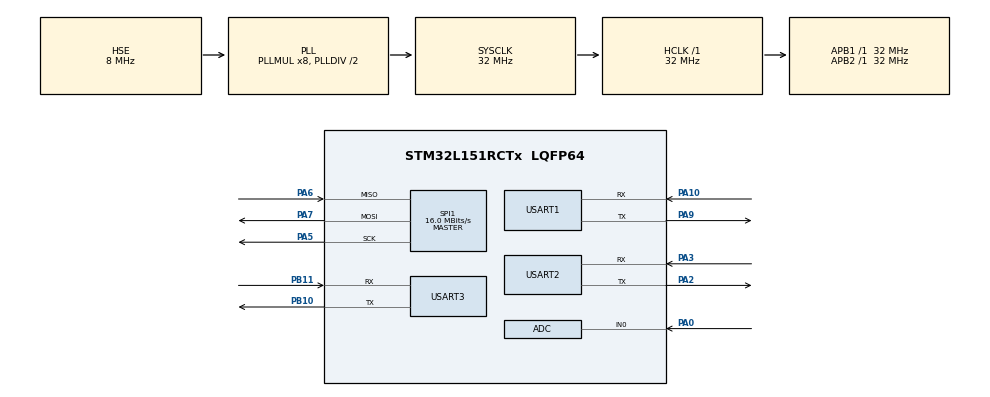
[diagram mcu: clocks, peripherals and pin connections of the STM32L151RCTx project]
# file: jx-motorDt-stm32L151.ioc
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ADC.Channel-8\#ChannelRegularConversion=ADC_CHANNEL_0
ADC.NbrOfConversionFlag=1
ADC.Rank-8\#ChannelRegularConversion=1
ADC.SamplingTime-8\#ChannelRegularConversion=ADC_SAMPLETIME_4CYCLES
Mcu.Family=STM32L1
Mcu.Name=STM32L151RCTx
Mcu.Package=LQFP64
NVIC.PriorityGroup=NVIC_PRIORITYGROUP_4
PA0-WKUP1.Mode=IN0
PA0-WKUP1.Signal=ADC_IN0
PA10.Mode=Asynchronous
PA10.Signal=USART1_RX
PA2.Mode=Asynchronous
PA2.Signal=USART2_TX
PA3.Mode=Asynchronous
PA3.Signal=USART2_RX
PA5.Mode=Full_Duplex_Master
PA5.Signal=SPI1_SCK
PA6.Mode=Full_Duplex_Master
PA6.Signal=SPI1_MISO
PA7.Mode=Full_Duplex_Master
PA7.Signal=SPI1_MOSI
PA9.Mode=Asynchronous
PA9.Signal=USART1_TX
PB10.Mode=Asynchronous
PB10.Signal=USART3_TX
PB11.Mode=Asynchronous
PB11.Signal=USART3_RX
PC14-OSC32_IN.Mode=LSE-External-Oscillator
PC14-OSC32_IN.Signal=RCC_OSC32_IN
PC15-OSC32_OUT.Mode=LSE-External-Oscillator
PC15-OSC32_OUT.Signal=RCC_OSC32_OUT
PH0-OSC_IN.Mode=HSE-External-Oscillator
PH0-OSC_IN.Signal=RCC_OSC_IN
PH1-OSC_OUT.Mode=HSE-External-Oscillator
PH1-OSC_OUT.Signal=RCC_OSC_OUT
ProjectManager.HeapSize=0x200
ProjectManager.StackSize=0x400
ProjectManager.TargetToolchain=MDK-ARM V4
RCC.48MHZClocksFreq_Value=32000000
RCC.AHBFreq_Value=32000000
RCC.APB1Freq_Value=32000000
RCC.APB1TimFreq_Value=32000000
RCC.APB2Freq_Value=32000000
RCC.APB2TimFreq_Value=32000000
RCC.HCLKFreq_Value=32000000
RCC.HSE_VALUE=8000000
RCC.HSI_VALUE=16000000
RCC.MSI_VALUE=2097000
RCC.PLLMUL=RCC_PLL_MUL8
RCC.PLLSourceVirtual=RCC_PLLSOURCE_HSE
RCC.SYSCLKFreq_VALUE=32000000
RCC.SYSCLKSource=RCC_SYSCLKSOURCE_PLLCLK
RCC.VCOOutputFreq_Value=64000000
SPI1.CalculateBaudRate=16.0 MBits/s
SPI1.Direction=SPI_DIRECTION_2LINES
SPI1.Mode=SPI_MODE_MASTER
SPI1.VirtualType=VM_MASTER
USART1.VirtualMode=VM_ASYNC
USART2.VirtualMode=VM_ASYNC
USART3.VirtualMode=VM_ASYNC
VP_TIM2_VS_ClockSourceITR.Mode=TriggerSource_ITR0
VP_TIM2_VS_ControllerModeClock.Mode=Clock Mode
VP_WWDG_VS_WWDG.Mode=WWDG_Activate
board=jx-motorDt-stm32L151

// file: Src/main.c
/**
  ******************************************************************************
  * @file           : main.c
  * @brief          : Main program body
  ******************************************************************************
  ** This notice applies to any and all portions of this file
  * that are not between comment pairs USER CODE BEGIN and
  * USER CODE END. Other portions of this file, whether
  * inserted by the user or by software development tools
  * are owned by their respective copyright owners.
  *
  * COPYRIGHT(c) 2018 STMicroelectronics
  *
  * Redistribution and use in source and binary forms, with or without modification,
  * are permitted provided that the following conditions are met:
  *   1. Redistributions of source code must retain the above copyright notice,
  *      this list of conditions and the following disclaimer.
  *   2. Redistributions in binary form must reproduce the above copyright notice,
  *      this list of conditions and the following disclaimer in the documentation
  *      and/or other materials provided with the distribution.
  *   3. Neither the name of STMicroelectronics nor the names of its contributors
  *      may be used to endorse or promote products derived from this software
  *      without specific prior written permission.
  *
  * THIS SOFTWARE IS PROVIDED BY THE COPYRIGHT HOLDERS AND CONTRIBUTORS "AS IS"
  * AND ANY EXPRESS OR IMPLIED WARRANTIES, INCLUDING, BUT NOT LIMITED TO, THE
  * IMPLIED WARRANTIES OF MERCHANTABILITY AND FITNESS FOR A PARTICULAR PURPOSE ARE
  * DISCLAIMED. IN NO EVENT SHALL THE COPYRIGHT HOLDER OR CONTRIBUTORS BE LIABLE
  * FOR ANY DIRECT, INDIRECT, INCIDENTAL, SPECIAL, EXEMPLARY, OR CONSEQUENTIAL
  * DAMAGES (INCLUDING, BUT NOT LIMITED TO, PROCUREMENT OF SUBSTITUTE GOODS OR
  * SERVICES; LOSS OF USE, DATA, OR PROFITS; OR BUSINESS INTERRUPTION) HOWEVER
  * CAUSED AND ON ANY THEORY OF LIABILITY, WHETHER IN CONTRACT, STRICT LIABILITY,
  * OR TORT (INCLUDING NEGLIGENCE OR OTHERWISE) ARISING IN ANY WAY OUT OF THE USE
  * OF THIS SOFTWARE, EVEN IF ADVISED OF THE POSSIBILITY OF SUCH DAMAGE.
  *
  ******************************************************************************
  */
#include "main.h"
#include "stm32l1xx_hal.h"

ADC_HandleTypeDef hadc;

SPI_HandleTypeDef hspi1;

TIM_HandleTypeDef htim2;

UART_HandleTypeDef huart1;
UART_HandleTypeDef huart2;
UART_HandleTypeDef huart3;

WWDG_HandleTypeDef hwwdg;

/* USER CODE BEGIN PV */
/* Private variables ---------------------------------------------------------*/

/* USER CODE END PV */

void SystemClock_Config(void);
static void MX_GPIO_Init(void);
static void MX_ADC_Init(void);
static void MX_WWDG_Init(void);
static void MX_USART1_UART_Init(void);
static void MX_USART2_UART_Init(void);
static void MX_USART3_UART_Init(void);
static void MX_SPI1_Init(void);
static void MX_TIM2_Init(void);
extern void DSP_FFT1024(void);
/* USER CODE BEGIN PFP */
/* Private function prototypes -----------------------------------------------*/

/* USER CODE END PFP */

int main(void)
{

  /* MCU Configuration----------------------------------------------------------*/

  /* Reset of all peripherals, Initializes the Flash interface and the Systick. */
  HAL_Init();

  /* Configure the system clock */
  SystemClock_Config();

  /* Initialize all configured peripherals */
  MX_GPIO_Init();
  MX_ADC_Init();
  MX_WWDG_Init();
  MX_USART1_UART_Init();
  MX_USART2_UART_Init();
  MX_USART3_UART_Init();
  MX_SPI1_Init();
  MX_TIM2_Init();

  /* Infinite loop */
  /* USER CODE BEGIN WHILE */
  DSP_FFT1024();
  while (1)
  {

  /* USER CODE END WHILE */

  }

}

void SystemClock_Config(void)
{

  RCC_OscInitTypeDef RCC_OscInitStruct;
  RCC_ClkInitTypeDef RCC_ClkInitStruct;

    /**Configure the main internal regulator output voltage
    */
  __HAL_PWR_VOLTAGESCALING_CONFIG(PWR_REGULATOR_VOLTAGE_SCALE1);

    /**Initializes the CPU, AHB and APB busses clocks
    */
  RCC_OscInitStruct.OscillatorType = RCC_OSCILLATORTYPE_HSI|RCC_OSCILLATORTYPE_HSE;
  RCC_OscInitStruct.HSEState = RCC_HSE_ON;
  RCC_OscInitStruct.HSIState = RCC_HSI_ON;
  RCC_OscInitStruct.HSICalibrationValue = 16;
  RCC_OscInitStruct.PLL.PLLState = RCC_PLL_ON;
  RCC_OscInitStruct.PLL.PLLSource = RCC_PLLSOURCE_HSE;
  RCC_OscInitStruct.PLL.PLLMUL = RCC_PLL_MUL8;
  RCC_OscInitStruct.PLL.PLLDIV = RCC_PLL_DIV2;
  if (HAL_RCC_OscConfig(&RCC_OscInitStruct) != HAL_OK)
  {
    _Error_Handler(__FILE__, __LINE__);
  }

    /**Initializes the CPU, AHB and APB busses clocks
    */
  RCC_ClkInitStruct.ClockType = RCC_CLOCKTYPE_HCLK|RCC_CLOCKTYPE_SYSCLK
                              |RCC_CLOCKTYPE_PCLK1|RCC_CLOCKTYPE_PCLK2;
  RCC_ClkInitStruct.SYSCLKSource = RCC_SYSCLKSOURCE_PLLCLK;
  RCC_ClkInitStruct.AHBCLKDivider = RCC_SYSCLK_DIV1;
  RCC_ClkInitStruct.APB1CLKDivider = RCC_HCLK_DIV1;
  RCC_ClkInitStruct.APB2CLKDivider = RCC_HCLK_DIV1;

  if (HAL_RCC_ClockConfig(&RCC_ClkInitStruct, FLASH_LATENCY_1) != HAL_OK)
  {
    _Error_Handler(__FILE__, __LINE__);
  }

    /**Configure the Systick interrupt time
    */
  HAL_SYSTICK_Config(HAL_RCC_GetHCLKFreq()/1000);

    /**Configure the Systick
    */
  HAL_SYSTICK_CLKSourceConfig(SYSTICK_CLKSOURCE_HCLK);

  /* SysTick_IRQn interrupt configuration */
  HAL_NVIC_SetPriority(SysTick_IRQn, 0, 0);
}

/* ADC init function */
static void MX_ADC_Init(void)
{

  ADC_ChannelConfTypeDef sConfig;

    /**Configure the global features of the ADC (Clock, Resolution, Data Alignment and number of conversion)
    */
  hadc.Instance = ADC1;
  hadc.Init.ClockPrescaler = ADC_CLOCK_ASYNC_DIV1;
  hadc.Init.Resolution = ADC_RESOLUTION_12B;
  hadc.Init.DataAlign = ADC_DATAALIGN_RIGHT;
  hadc.Init.ScanConvMode = ADC_SCAN_DISABLE;
  hadc.Init.EOCSelection = ADC_EOC_SEQ_CONV;
  hadc.Init.LowPowerAutoWait = ADC_AUTOWAIT_DISABLE;
  hadc.Init.LowPowerAutoPowerOff = ADC_AUTOPOWEROFF_DISABLE;
  hadc.Init.ChannelsBank = ADC_CHANNELS_BANK_A;
  hadc.Init.ContinuousConvMode = DISABLE;
  hadc.Init.NbrOfConversion = 1;
  hadc.Init.DiscontinuousConvMode = DISABLE;
  hadc.Init.ExternalTrigConv = ADC_SOFTWARE_START;
  hadc.Init.ExternalTrigConvEdge = ADC_EXTERNALTRIGCONVEDGE_NONE;
  hadc.Init.DMAContinuousRequests = DISABLE;
  if (HAL_ADC_Init(&hadc) != HAL_OK)
  {
    _Error_Handler(__FILE__, __LINE__);
  }

    /**Configure for the selected ADC regular channel its corresponding rank in the sequencer and its sample time.
    */
  sConfig.Channel = ADC_CHANNEL_0;
  sConfig.Rank = ADC_REGULAR_RANK_1;
  sConfig.SamplingTime = ADC_SAMPLETIME_4CYCLES;
  if (HAL_ADC_ConfigChannel(&hadc, &sConfig) != HAL_OK)
  {
    _Error_Handler(__FILE__, __LINE__);
  }

}

/* SPI1 init function */
static void MX_SPI1_Init(void)
{

  /* SPI1 parameter configuration*/
  hspi1.Instance = SPI1;
  hspi1.Init.Mode = SPI_MODE_MASTER;
  hspi1.Init.Direction = SPI_DIRECTION_2LINES;
  hspi1.Init.DataSize = SPI_DATASIZE_8BIT;
  hspi1.Init.CLKPolarity = SPI_POLARITY_LOW;
  hspi1.Init.CLKPhase = SPI_PHASE_1EDGE;
  hspi1.Init.NSS = SPI_NSS_SOFT;
  hspi1.Init.BaudRatePrescaler = SPI_BAUDRATEPRESCALER_2;
  hspi1.Init.FirstBit = SPI_FIRSTBIT_MSB;
  hspi1.Init.TIMode = SPI_TIMODE_DISABLE;
  hspi1.Init.CRCCalculation = SPI_CRCCALCULATION_DISABLE;
  hspi1.Init.CRCPolynomial = 10;
  if (HAL_SPI_Init(&hspi1) != HAL_OK)
  {
    _Error_Handler(__FILE__, __LINE__);
  }

}

/* TIM2 init function */
static void MX_TIM2_Init(void)
{

  TIM_SlaveConfigTypeDef sSlaveConfig;
  TIM_MasterConfigTypeDef sMasterConfig;

  htim2.Instance = TIM2;
  htim2.Init.Prescaler = 0;
  htim2.Init.CounterMode = TIM_COUNTERMODE_UP;
  htim2.Init.Period = 0;
  htim2.Init.ClockDivision = TIM_CLOCKDIVISION_DIV1;
  if (HAL_TIM_Base_Init(&htim2) != HAL_OK)
  {
    _Error_Handler(__FILE__, __LINE__);
  }

  sSlaveConfig.SlaveMode = TIM_SLAVEMODE_EXTERNAL1;
  sSlaveConfig.InputTrigger = TIM_TS_ITR0;
  if (HAL_TIM_SlaveConfigSynchronization(&htim2, &sSlaveConfig) != HAL_OK)
  {
    _Error_Handler(__FILE__, __LINE__);
  }

  sMasterConfig.MasterOutputTrigger = TIM_TRGO_RESET;
  sMasterConfig.MasterSlaveMode = TIM_MASTERSLAVEMODE_DISABLE;
  if (HAL_TIMEx_MasterConfigSynchronization(&htim2, &sMasterConfig) != HAL_OK)
  {
    _Error_Handler(__FILE__, __LINE__);
  }

}

/* USART1 init function */
static void MX_USART1_UART_Init(void)
{

  huart1.Instance = USART1;
  huart1.Init.BaudRate = 115200;
  huart1.Init.WordLength = UART_WORDLENGTH_8B;
  huart1.Init.StopBits = UART_STOPBITS_1;
  huart1.Init.Parity = UART_PARITY_NONE;
  huart1.Init.Mode = UART_MODE_TX_RX;
  huart1.Init.HwFlowCtl = UART_HWCONTROL_NONE;
  huart1.Init.OverSampling = UART_OVERSAMPLING_16;
  if (HAL_UART_Init(&huart1) != HAL_OK)
  {
    _Error_Handler(__FILE__, __LINE__);
  }

}

/* USART2 init function */
static void MX_USART2_UART_Init(void)
{

  huart2.Instance = USART2;
  huart2.Init.BaudRate = 115200;
  huart2.Init.WordLength = UART_WORDLENGTH_8B;
  huart2.Init.StopBits = UART_STOPBITS_1;
  huart2.Init.Parity = UART_PARITY_NONE;
  huart2.Init.Mode = UART_MODE_TX_RX;
  huart2.Init.HwFlowCtl = UART_HWCONTROL_NONE;
  huart2.Init.OverSampling = UART_OVERSAMPLING_16;
  if (HAL_UART_Init(&huart2) != HAL_OK)
  {
    _Error_Handler(__FILE__, __LINE__);
  }

}

/* USART3 init function */
static void MX_USART3_UART_Init(void)
{

  huart3.Instance = USART3;
  huart3.Init.BaudRate = 115200;
  huart3.Init.WordLength = UART_WORDLENGTH_8B;
  huart3.Init.StopBits = UART_STOPBITS_1;
  huart3.Init.Parity = UART_PARITY_NONE;
  huart3.Init.Mode = UART_MODE_TX_RX;
  huart3.Init.HwFlowCtl = UART_HWCONTROL_NONE;
  huart3.Init.OverSampling = UART_OVERSAMPLING_16;
  if (HAL_UART_Init(&huart3) != HAL_OK)
  {
    _Error_Handler(__FILE__, __LINE__);
  }

}

/* WWDG init function */
static void MX_WWDG_Init(void)
{

  hwwdg.Instance = WWDG;
  hwwdg.Init.Prescaler = WWDG_PRESCALER_1;
  hwwdg.Init.Window = 64;
  hwwdg.Init.Counter = 64;
  hwwdg.Init.EWIMode = WWDG_EWI_DISABLE;
  if (HAL_WWDG_Init(&hwwdg) != HAL_OK)
  {
    _Error_Handler(__FILE__, __LINE__);
  }

}

/** Configure pins as
        * Analog
        * Input
        * Output
        * EVENT_OUT
        * EXTI
*/
static void MX_GPIO_Init(void)
{

  /* GPIO Ports Clock Enable */
  __HAL_RCC_GPIOC_CLK_ENABLE();
  __HAL_RCC_GPIOH_CLK_ENABLE();
  __HAL_RCC_GPIOA_CLK_ENABLE();
  __HAL_RCC_GPIOB_CLK_ENABLE();

}

void _Error_Handler(char *file, int line)
{
  while(1)
  {
  }
}

/************************ (C) COPYRIGHT STMicroelectronics *****END OF FILE****/
